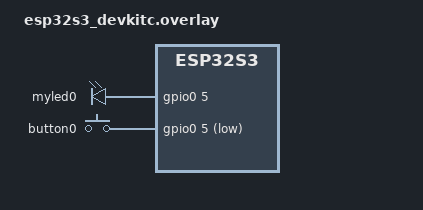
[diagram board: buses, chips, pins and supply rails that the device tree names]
/ {
    aliases {
        my-led = &myled0;
        my-button = &button0;
    };

    leds {
        compatible = "gpio-leds";
        myled0: d13 {
            gpios = <&gpio0 5 GPIO_ACTIVE_HIGH>;
        };
    };

    buttons {
        compatible = "gpio-keys";
        button0: button_0 {
            gpios = <&gpio0 5 (GPIO_ACTIVE_LOW | GPIO_PULL_UP)>;
        };
    };
};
